AUTOSAR XML (schema 4-3-0)
package /ComponentTypes
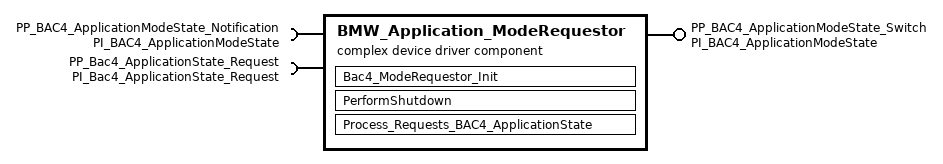
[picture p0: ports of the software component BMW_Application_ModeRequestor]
  complex device driver sw component type BMW_Application_ModeRequestor
    provide port PP_BAC4_ApplicationModeState_Switch: mode-switch-sender-com-spec{enhanced-mode-api=false, mode-group=Bac4_ApplicationMode, queue-length=3}, provided-interface=PI_BAC4_ApplicationModeState
    require port PP_BAC4_ApplicationModeState_Notification: mode-switch-receiver-com-spec{enhanced-mode-api=true, supports-asynchronous-mode-switch=false}, required-interface=PI_BAC4_ApplicationModeState
    require port PP_Bac4_ApplicationState_Request: nonqueued-receiver-com-spec{data-element=Bac4_ApplicationState, filter=data-filter-type=ALWAYS, init-value=constant-reference=C_Bac4_ApplicationState_INIT}, required-interface=PI_Bac4_ApplicationState_Request
    behavior BMW_Application_ModeRequestor_InternalBehavior: data-type-mapping=TMS_Bac4_ApplicationState, included-data-type-set{data-type=Bac4_ApplicationStateType, literal-prefix=BAC4_ApplicationStateSet}
      init event Bac4_ModeRequestor_InitEvent: start-on-event=Bac4_ModeRequestor_Init
      swc mode switch event MST_PerformShutdown_0: start-on-event=PerformShutdown, activation=ON-ENTRY, mode=PP_BAC4_ApplicationModeState_Notification.Bac4_ApplicationMode.SHUTDOWN
      swc mode switch event MST_Process_Requests_BAC4_ApplicationState_1: start-on-event=Process_Requests_BAC4_ApplicationState, activation=ON-ENTRY, mode=PP_BAC4_ApplicationModeState_Notification.Bac4_ApplicationMode.POST_RUN
      data received event DRT_Process_Requests_BAC4_ApplicationState_PP_Bac4_ApplicationState_Request_Bac4_ApplicationState: start-on-event=Process_Requests_BAC4_ApplicationState, data=PP_Bac4_ApplicationState_Request.Bac4_ApplicationState
      runnable Bac4_ModeRequestor_Init
        mode switch point SWITCH_PP_BAC4_ApplicationModeState_Switch_Bac4_ApplicationMode: mode-group=PP_BAC4_ApplicationModeState_Switch.Bac4_ApplicationMode
      runnable PerformShutdown: mode-access-point=PP_BAC4_ApplicationModeState_Notification.Bac4_ApplicationMode
        mode switch point SWITCH_PP_BAC4_ApplicationModeState_Switch_Bac4_ApplicationMode: mode-group=PP_BAC4_ApplicationModeState_Switch.Bac4_ApplicationMode
      runnable Process_Requests_BAC4_ApplicationState: mode-access-point=PP_BAC4_ApplicationModeState_Notification.Bac4_ApplicationMode
        data-receive-point-by-arguments:
          access REC_PP_Bac4_ApplicationState_Request_Bac4_ApplicationState: accessed-variable=PP_Bac4_ApplicationState_Request.Bac4_ApplicationState
        mode switch point SWITCH_PP_BAC4_ApplicationModeState_Switch_Bac4_ApplicationMode: mode-group=PP_BAC4_ApplicationModeState_Switch.Bac4_ApplicationMode
  swc implementation BMW_Application_ModeRequestor_Implementation: behavior=BMW_Application_ModeRequestor_InternalBehavior
    code-descriptors:
      code Default: artifact-descriptors=autosar-engineering-object={short-label=Default, category=SWSRC}
